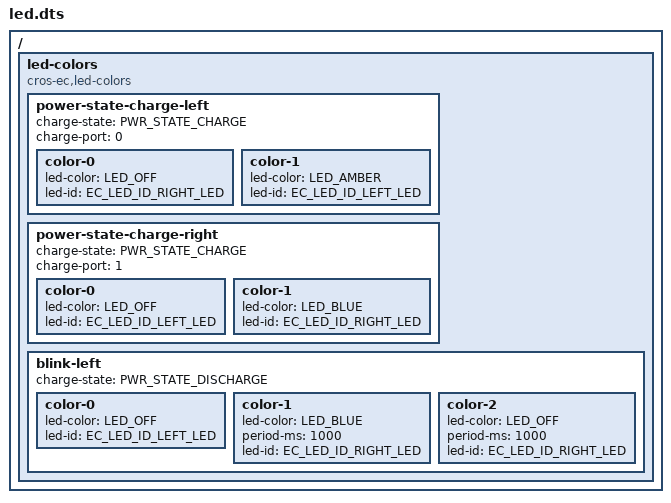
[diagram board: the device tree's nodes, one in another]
/ {
	led-colors {
		compatible = "cros-ec,led-colors";

		power-state-charge-left {
			charge-state = "PWR_STATE_CHARGE";
			charge-port = <0>;

			color-0 {
				led-color = "LED_OFF";
				led-id = "EC_LED_ID_RIGHT_LED";
			};
			color-1 {
				led-color = "LED_AMBER";
				led-id = "EC_LED_ID_LEFT_LED";
			};
		};

		power-state-charge-right {
			charge-state = "PWR_STATE_CHARGE";
			charge-port = <1>;

			color-0 {
				led-color = "LED_OFF";
				led-id = "EC_LED_ID_LEFT_LED";
			};
			color-1 {
				led-color = "LED_BLUE";
				led-id = "EC_LED_ID_RIGHT_LED";
			};
		};

		blink-left {
			charge-state = "PWR_STATE_DISCHARGE";

			color-0 {
				led-color = "LED_OFF";
				led-id = "EC_LED_ID_LEFT_LED";
			};
			color-1 {
				led-color = "LED_BLUE";
				period-ms = <1000>;
				led-id = "EC_LED_ID_RIGHT_LED";
			};
			color-2 {
				led-color = "LED_OFF";
				period-ms = <1000>;
				led-id = "EC_LED_ID_RIGHT_LED";
			};
		};
	};
};
